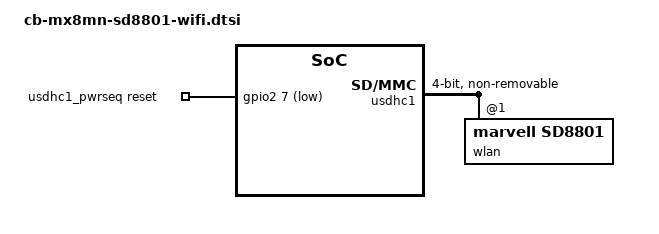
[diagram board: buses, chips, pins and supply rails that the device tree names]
/ {
	usdhc1_pwrseq: pwr_seq {
		compatible = "mmc-pwrseq-simple";
		reset-gpios = <&gpio2 7 GPIO_ACTIVE_LOW>;
		post-power-on-delay-ms = <100>;
		power-off-delay-us = <60>;
	};
};

&usdhc1 {
	#address-cells = <1>;
	#size-cells = <0>;
	pinctrl-names = "default", "state_100mhz", "state_200mhz";
	pinctrl-0 = <&pinctrl_usdhc1>, <&pinctrl_wlan>;
	bus-width = <4>;
	non-removable;
	no-1-8-v;
	mmc-pwrseq = <&usdhc1_pwrseq>;
	wifi-host;
	status = "okay";

    wlan@1 {
        compatible = "marvell,sd8801";
        reg = <1>;

        // Parameters can be found in README_MLAN located in
        // https://github.com/nxp-imx/mwifiex/blob/lf-6.1.1_1.0.0/mxm_wifiex/wlan_src/
        drvdbg = <0x6>;
        drv_mode = <0x3>;
        cfg80211_wext = <0xf>;
        cal_data_cfg = "none";
        ps_mode = <0>;
        auto_ds = <2>;
        host_mlme = <1>;
	};
};

&iomuxc {
    pinctrl-names = "default";

    imx8mn-evk {
        pinctrl_usdhc1: usdhc1grp {
            fsl,pins = <
                MX8MN_IOMUXC_SD1_CLK_USDHC1_CLK     0x190
                MX8MN_IOMUXC_SD1_CMD_USDHC1_CMD     0x1d0
                MX8MN_IOMUXC_SD1_DATA0_USDHC1_DATA0	0x1d0
                MX8MN_IOMUXC_SD1_DATA1_USDHC1_DATA1	0x1d0
                MX8MN_IOMUXC_SD1_DATA2_USDHC1_DATA2	0x1d0
                MX8MN_IOMUXC_SD1_DATA3_USDHC1_DATA3	0x1d0
            >;
        };

        pinctrl_wlan: wlangrp {
            fsl,pins = <
                MX8MN_IOMUXC_SD1_DATA5_GPIO2_IO7 0x00
            >;
        };
    };
};
